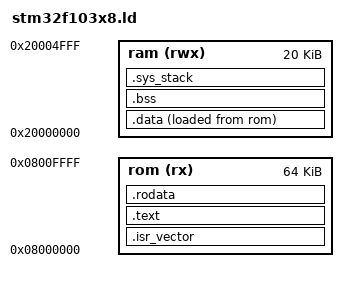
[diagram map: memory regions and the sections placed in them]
ENTRY(reset_handler)

MEMORY
{
    rom (rx)  : ORIGIN = 0x08000000, LENGTH = 64K
    ram (rwx) : ORIGIN = 0x20000000, LENGTH = 20K
}

SECTIONS
{
    .isr_vector :
    {
        . = ALIGN(4);
        KEEP(*(.isr_vector))
        . = ALIGN(4);
    } >rom

    .text : {
        . = ALIGN(4);
        *(.text)
        *(.text*)
        *(.glue_7)         /* glue arm to thumb code */
        *(.glue_7t)        /* glue thumb to arm code */
        *(.eh_frame)

        KEEP (*(.init))
        KEEP (*(.fini))

        . = ALIGN(4);
        _etext = .;
    } >rom

    .rodata :
    {
        . = ALIGN(4);
        *(.rodata)
        *(.rodata*)
        . = ALIGN(4);
    } >rom

    .data : {
        . = ALIGN(4);
        _data = .;
        *(.data)
        *(.data*)
        . = ALIGN(4);
        _edata = .;
    } >ram AT >rom
    _data_loadaddr = LOADADDR(.data);

    . = ALIGN(4);
    .bss : {
        _bss = .;
        *(.bss)
        *(.bss*)
        *(COMMON)
        . = ALIGN(4);
        _ebss = .;
    } >ram
    
    .sys_stack :
    {
        . = ALIGN(4);
        *(.sys_stack)
        . = ALIGN(4);
    } > ram

    . = ALIGN(4);
    .ARM.attributes 0 : { *(.ARM.attributes) }
}
